# haltium_cellcore register map
Vendor: Nordic Semiconductor; Series: nRFHaltium; File version: 1
CPU: CM33 r0p4, little endian, MPU, FPU, 3 interrupt priority bits, 480 interrupts
Registers are 32-bit, read-write, reset 0x0 unless marked. A register's access mark holds for its fields unless they carry their own. Offsets are from the block's base; [hi:lo] are bit positions; lines under a group give offsets from that group; {n}, {i} and the like mark numbered series; 'fields as' and 'values as' point back to an identical list.

## CPUCONF_NS — CPU Configuration 0
Base 0x44012000
Same registers: CPUCONF_S 0x54012000
0x00 TASKS_ERASECACHE wo — Erase the caches used by the CPU.
  [0] TASKS_ERASECACHE
    1=Trigger task
0x500 INITSVTOR — Initial value of the secure VTOR (Vector Table Offset Register) after CPU reset.
  [31:0] INITSVTOR — Initial value of the VTOR.
0x504 INITNSVTOR — Initial value of the non-secure VTOR (Vector Table Offset Register).
  [31:0] INITNSVTOR — Initial value of the VTOR.
0x508 CPUSTART — Enable for starting the CPU
  [0] EN — Enable to start the CPU.
    0=Stopped (CPU stopped.); 1=Started (CPU started.)
0x50C CPUWAIT — Enable for the CPU wait.
  [0] EN — Enable to the CPU wait.
    0=Disabled (CPU is not waiting.); 1=Enabled (CPU is waiting.)

## MEMCONF_NS — Memory configuration 0
Base 0x44013000
Same registers: MEMCONF_S 0x54013000
{0x500+0x10*i} POWER[{i}] (i=0..3) group — Unspecified
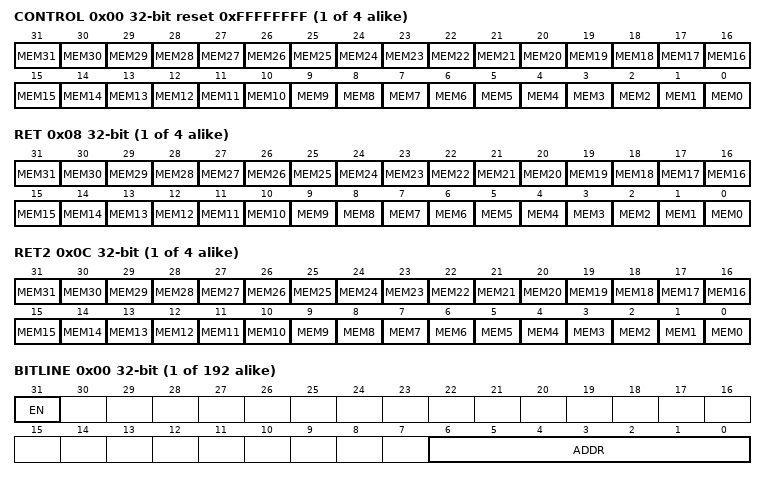
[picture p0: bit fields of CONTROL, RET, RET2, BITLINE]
  0x00 CONTROL reset 0xFFFFFFFF — Description cluster: RAM/ROM[n] power control register.
    [all] fields
      0=Off (Power down); 1=On (Power up)
    [n] MEM{n} (n=0..31) — Keep the RAM/ROM block MEM[{n}] on or off when in System ON mode.
  0x08 RET — Description cluster: RAM retention for RAM [n].
    [all] fields
      0=Off (Retention off); 1=On (Retention on)
    [n] MEM{n} (n=0..31) — Keep the RAM block MEM[{n}] retained when in System OFF mode.
  0x0C RET2 — Description cluster: RAM retention for the second bank in the RAM block
    [all] fields
      0=Off (Retention off); 1=On (Retention on)
    [n] MEM{n} (n=0..31) — Keep the second bank in RAM block MEM[{n}] retained when in System OFF mode.
{0x600+4i} REPAIR[{i}] (i=0..191) group — Unspecified
  0x00 BITLINE — Description cluster: Repair configuration for RAM blocks.
    [31] EN — Enable bitline repair
      0=Disabled (Repair disabled.); 1=Enabled (Repair enabled.)
    [6:0] ADDR — Repair address of the bitline
{0x900+4i} BLOCKTYPE[{i}] (i=0..63) group — Unspecified
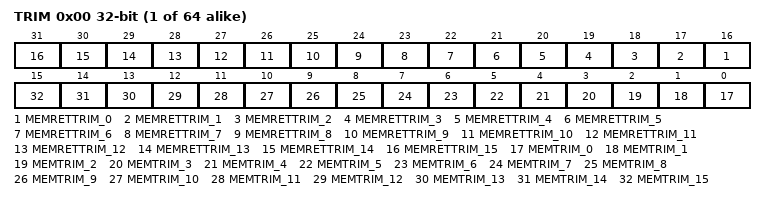
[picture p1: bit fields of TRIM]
  0x00 TRIM — Description cluster: Trim configuration for the RAM/ROM block types.
    [n+16] MEMRETTRIM_{n} (n=0..15) — Trimming for retention mode for decreased leakage. Must be kept active in RAM retention mode.
    [n] MEMTRIM_{n} (n=0..15) — Read/write margin trim.

## DPPIC0_NS — Distributed programmable peripheral interconnect controller 0
Base 0x44021000
Same registers: DPPIC1_NS 0x44032000, GLOBAL_DPPIC120_NS 0x4F8E1000, GLOBAL_DPPIC130_NS 0x4F922000, GLOBAL_DPPIC131_NS 0x4F981000, GLOBAL_DPPIC132_NS 0x4F991000, GLOBAL_DPPIC133_NS 0x4F9A1000, GLOBAL_DPPIC134_NS 0x4F9B1000, GLOBAL_DPPIC135_NS 0x4F9C1000, GLOBAL_DPPIC136_NS 0x4F9D1000, DPPIC0_S 0x54021000, DPPIC1_S 0x54032000, GLOBAL_DPPIC120_S 0x5F8E1000, GLOBAL_DPPIC130_S 0x5F922000, GLOBAL_DPPIC131_S 0x5F981000, GLOBAL_DPPIC132_S 0x5F991000, GLOBAL_DPPIC133_S 0x5F9A1000, GLOBAL_DPPIC134_S 0x5F9B1000, GLOBAL_DPPIC135_S 0x5F9C1000, GLOBAL_DPPIC136_S 0x5F9D1000
{0x0+8i} TASKS_CHG[{i}] (i=0..1) group — Channel group tasks
  0x00 EN wo — Description cluster: Enable channel group n
    [0] EN — Enable channel group n
      1=Trigger task
  0x04 DIS wo — Description cluster: Disable channel group n
    [0] DIS — Disable channel group n
      1=Trigger task
{0x80+8i} SUBSCRIBE_CHG[{i}] (i=0..1) group — Subscribe configuration for tasks
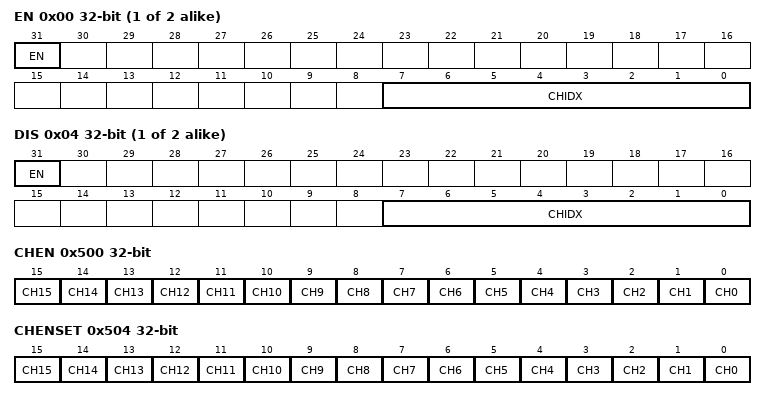
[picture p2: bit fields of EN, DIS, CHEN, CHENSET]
  0x00 EN — Description cluster: Subscribe configuration for task CHG[n].EN
    [31] EN
      0=Disabled (Disable subscription); 1=Enabled (Enable subscription)
    [7:0] CHIDX — DPPI channel that task CHG[n].EN will subscribe to
  0x04 DIS — Description cluster: Subscribe configuration for task CHG[n].DIS
    [31] EN
      values as SUBSCRIBE_CHG[0].EN.EN
    [7:0] CHIDX — DPPI channel that task CHG[n].DIS will subscribe to
0x500 CHEN — Channel enable register
  [all] fields
    0=Disabled (Disable channel); 1=Enabled (Enable channel)
  [n] CH{n} (n=0..15) — Enable or disable channel {n}
0x504 CHENSET write-1-sets — Channel enable set register
  [all] fields
    on read: 0=Disabled (Read: Channel disabled); 1=Enabled (Read: Channel enabled) | on write: 1=Set (Write: Enable channel)
  [n] CH{n} (n=0..15) — Channel {n} enable set register. Writing 0 has no effect.
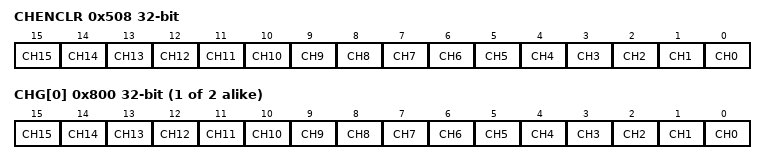
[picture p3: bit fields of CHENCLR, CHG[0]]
0x508 CHENCLR write-1-clears — Channel enable clear register
  [all] fields
    on read: 0=Disabled (Read: Channel disabled); 1=Enabled (Read: Channel enabled) | on write: 1=Clear (Write: Disable channel)
  [n] CH{n} (n=0..15) — Channel {n} enable clear register. Writing 0 has no effect.
{0x800+4i} CHG[{i}] (i=0..1) — Description collection: Channel group n Note: Writes to this register are ignored if either SUBSCRIBE_CHG[n].EN or SUBSCRIBE_CHG[n].DIS is enabled
  [all] fields
    0=Excluded; 1=Included
  [n] CH{n} (n=0..15) — Include or exclude channel {n}
